# ESP32-C6 register map
Vendor: ESPRESSIF SYSTEMS (SHANGHAI) CO., LTD.; Series: ESP32 C-Series; File version: 5
CPU: RV32IMAC r0p0, little endian, no MPU, no FPU, 4 interrupt priority bits
Address unit: 32 bits
Registers are 32-bit, read-write, reset 0x0 unless marked. A register's access mark holds for its fields unless they carry their own. Offsets are from the block's base; [hi:lo] are bit positions; {n}, {i} and the like mark numbered series.

## DS — Digital Signature
Base 0x6008C000
{0x0+i} Y_MEM[{i}] (i=0..511) 8-bit access not given — memory that stores Y
{0x200+i} M_MEM[{i}] (i=0..511) 8-bit access not given — memory that stores M
{0x400+i} RB_MEM[{i}] (i=0..511) 8-bit access not given — memory that stores Rb
{0x600+i} BOX_MEM[{i}] (i=0..47) 8-bit access not given — memory that stores BOX
{0x630+i} IV_MEM[{i}] (i=0..15) 8-bit access not given — memory that stores IV
{0x800+i} X_MEM[{i}] (i=0..511) 8-bit access not given — memory that stores X
{0xA00+i} Z_MEM[{i}] (i=0..511) 8-bit access not given — memory that stores Z
0xE00 SET_START wo — DS start control register
  [0] SET_START — set this bit to start DS operation.
0xE04 SET_CONTINUE wo — DS continue control register
  [0] SET_CONTINUE — set this bit to continue DS operation.
0xE08 SET_FINISH wo — DS finish control register
  [0] SET_FINISH — Set this bit to finish DS process.
0xE0C QUERY_BUSY ro — DS query busy register
  [0] QUERY_BUSY — digital signature state. 1'b0: idle, 1'b1: busy
0xE10 QUERY_KEY_WRONG ro — DS query key-wrong counter register
  [3:0] QUERY_KEY_WRONG — digital signature key wrong counter
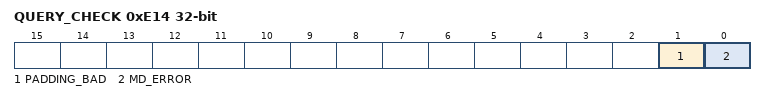
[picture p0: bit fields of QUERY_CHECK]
0xE14 QUERY_CHECK ro — DS query check result register
  [1] PADDING_BAD — padding checkout result. 1'b0: a good padding, 1'b1: a bad padding
  [0] MD_ERROR — MD checkout result. 1'b0: MD check pass, 1'b1: MD check fail
0xE20 DATE reset 0x20200618 — DS version control register
  [29:0] DATE — ds version information

## ECC — ECC (ECC Hardware Accelerator)
Base 0x6008B000
0x0C MULT_INT_RAW ro — ECC interrupt raw register, valid in level.
  [0] CALC_DONE_INT_RAW — The raw interrupt status bit for the ecc_calc_done_int interrupt
0x10 MULT_INT_ST ro — ECC interrupt status register.
  [0] CALC_DONE_INT_ST — The masked interrupt status bit for the ecc_calc_done_int interrupt
0x14 MULT_INT_ENA — ECC interrupt enable register.
  [0] CALC_DONE_INT_ENA — The interrupt enable bit for the ecc_calc_done_int interrupt
0x18 MULT_INT_CLR wo — ECC interrupt clear register.
  [0] CALC_DONE_INT_CLR — Set this bit to clear the ecc_calc_done_int interrupt
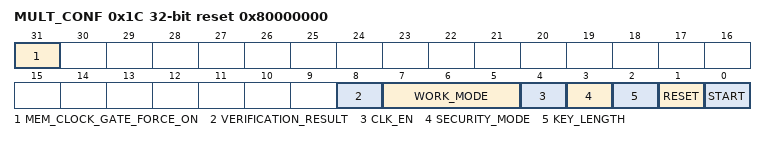
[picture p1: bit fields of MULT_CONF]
0x1C MULT_CONF access per field reset 0x80000000 — ECC configure register
  [31] MEM_CLOCK_GATE_FORCE_ON rw — ECC memory clock gate force on register
  [8] VERIFICATION_RESULT ro — The verification result bit of ECC Accelerator, only valid when calculation is done.
  [7:5] WORK_MODE rw — The work mode bits of ECC Accelerator. 0: Point Mult Mode. 1: Division mode. 2: Point verification mode. 3: Point Verif+mult mode. 4: Jacobian Point Mult Mode. 5: Reserved. 6: Jacobian Point Verification Mode. 7: Point Verif + Jacobian Mult Mode.
  [4] CLK_EN rw — Write 1 to force on register clock gate.
  [3] SECURITY_MODE rw — Reserved
  [2] KEY_LENGTH rw — The key length mode bit of ECC Accelerator. 0: P-192. 1: P-256.
  [1] RESET wo — Write 1 to reset ECC Accelerator.
  [0] START rw — Write 1 to start caculation of ECC Accelerator. This bit will be self-cleared after the caculatrion is done.
0xFC MULT_DATE reset 0x2201240 — Version control register
  [27:0] DATE — ECC mult version control register
{0x100+i} K_MEM[{i}] (i=0..31) 8-bit access not given — The memory that stores k.
{0x120+i} PX_MEM[{i}] (i=0..31) 8-bit access not given — The memory that stores Px.
{0x140+i} PY_MEM[{i}] (i=0..31) 8-bit access not given — The memory that stores Py.

## GPIO_SD — Sigma-Delta Modulation
Base 0x60004F00
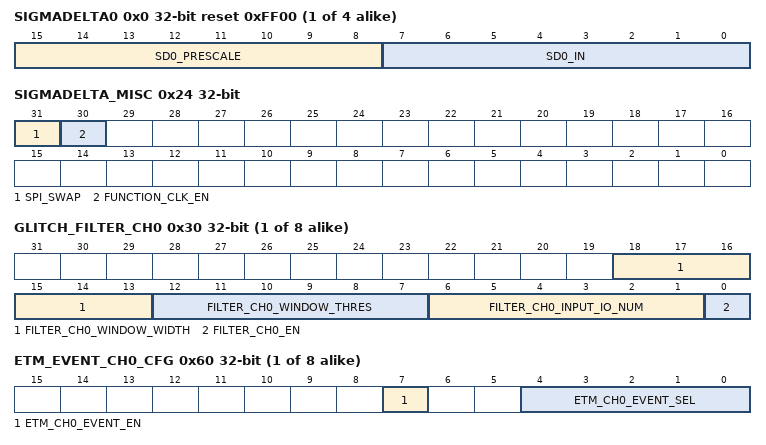
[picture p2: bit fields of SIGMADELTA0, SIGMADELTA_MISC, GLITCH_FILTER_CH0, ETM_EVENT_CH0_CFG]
{0x0+4i} SIGMADELTA{i} (i=0..3) reset 0xFF00 — Duty Cycle Configure Register of SDM{i}
  [15:8] SD0_PRESCALE — This field is used to set a divider value to divide APB clock.
  [7:0] SD0_IN — This field is used to configure the duty cycle of sigma delta modulation output.
0x20 CLOCK_GATE — Clock Gating Configure Register
  [0] CLK_EN — Clock enable bit of configuration registers for sigma delta modulation.
0x24 SIGMADELTA_MISC — MISC Register
  [31] SPI_SWAP — Reserved.
  [30] FUNCTION_CLK_EN — Clock enable bit of sigma delta modulation.
{0x30+4i} GLITCH_FILTER_CH{i} (i=0..7) — Glitch Filter Configure Register of Channel{i}
  [18:13] FILTER_CH0_WINDOW_WIDTH — Glitch Filter window width.
  [12:7] FILTER_CH0_WINDOW_THRES — Glitch Filter window threshold.
  [6:1] FILTER_CH0_INPUT_IO_NUM — Glitch Filter input io number.
  [0] FILTER_CH0_EN — Glitch Filter channel enable bit.
{0x60+4i} ETM_EVENT_CH{i}_CFG (i=0..7) — Etm Config register of Channel{i}
  [7] ETM_CH0_EVENT_EN — Etm event send enable bit.
  [4:0] ETM_CH0_EVENT_SEL — Etm event channel select gpio.
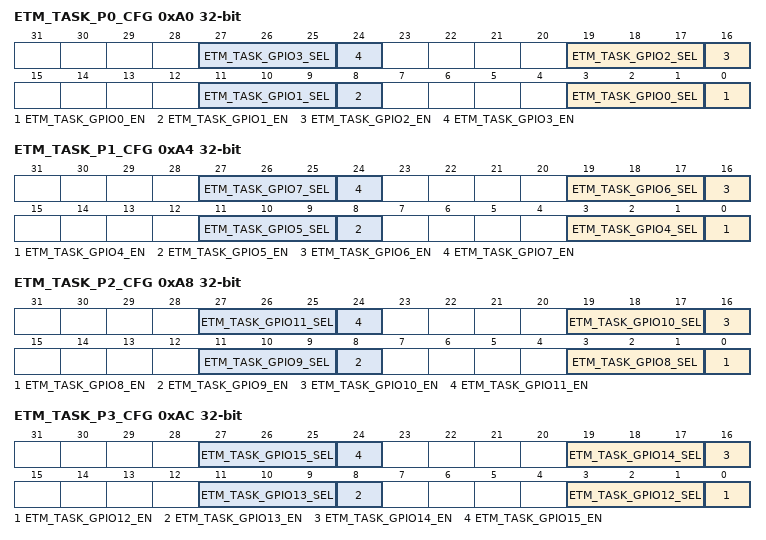
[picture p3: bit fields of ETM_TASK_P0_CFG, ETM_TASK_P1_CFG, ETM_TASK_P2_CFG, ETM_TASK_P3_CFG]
0xA0 ETM_TASK_P0_CFG — Etm Configure Register to decide which GPIO been chosen
  [8n+3:8n+1] ETM_TASK_GPIO{n}_SEL (n=0..3) — GPIO choose a etm task channel.
  [8n] ETM_TASK_GPIO{n}_EN (n=0..3) — Enable bit of GPIO response etm task.
0xA4 ETM_TASK_P1_CFG — Etm Configure Register to decide which GPIO been chosen
  [8n-29:8n-31] ETM_TASK_GPIO{n}_SEL (n=4..7) — GPIO choose a etm task channel.
  [8n-32] ETM_TASK_GPIO{n}_EN (n=4..7) — Enable bit of GPIO response etm task.
0xA8 ETM_TASK_P2_CFG — Etm Configure Register to decide which GPIO been chosen
  [8n-61:8n-63] ETM_TASK_GPIO{n}_SEL (n=8..11) — GPIO choose a etm task channel.
  [8n-64] ETM_TASK_GPIO{n}_EN (n=8..11) — Enable bit of GPIO response etm task.
0xAC ETM_TASK_P3_CFG — Etm Configure Register to decide which GPIO been chosen
  [8n-93:8n-95] ETM_TASK_GPIO{n}_SEL (n=12..15) — GPIO choose a etm task channel.
  [8n-96] ETM_TASK_GPIO{n}_EN (n=12..15) — Enable bit of GPIO response etm task.
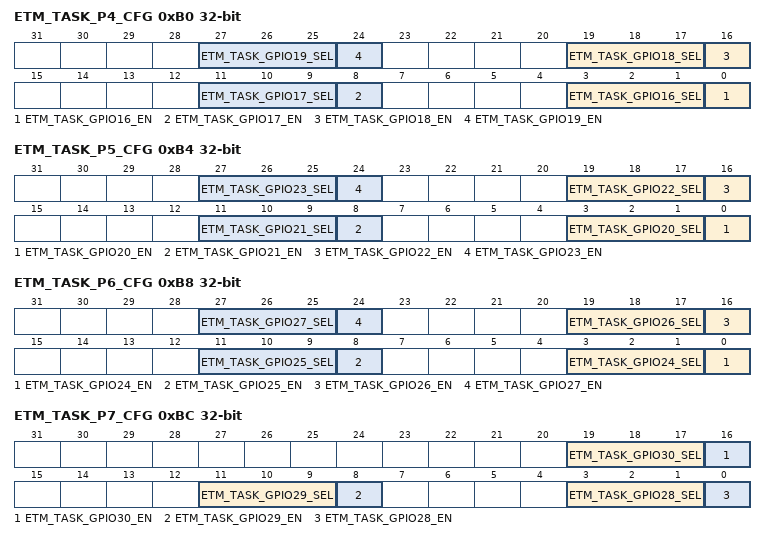
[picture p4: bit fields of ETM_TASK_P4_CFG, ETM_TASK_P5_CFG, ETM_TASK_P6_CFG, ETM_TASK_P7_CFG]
0xB0 ETM_TASK_P4_CFG — Etm Configure Register to decide which GPIO been chosen
  [8n-125:8n-127] ETM_TASK_GPIO{n}_SEL (n=16..19) — GPIO choose a etm task channel.
  [8n-128] ETM_TASK_GPIO{n}_EN (n=16..19) — Enable bit of GPIO response etm task.
0xB4 ETM_TASK_P5_CFG — Etm Configure Register to decide which GPIO been chosen
  [8n-157:8n-159] ETM_TASK_GPIO{n}_SEL (n=20..23) — GPIO choose a etm task channel.
  [8n-160] ETM_TASK_GPIO{n}_EN (n=20..23) — Enable bit of GPIO response etm task.
0xB8 ETM_TASK_P6_CFG — Etm Configure Register to decide which GPIO been chosen
  [8n-189:8n-191] ETM_TASK_GPIO{n}_SEL (n=24..27) — GPIO choose a etm task channel.
  [8n-192] ETM_TASK_GPIO{n}_EN (n=24..27) — Enable bit of GPIO response etm task.
0xBC ETM_TASK_P7_CFG — Etm Configure Register to decide which GPIO been chosen
  [19:17] ETM_TASK_GPIO30_SEL — GPIO choose a etm task channel.
  [16] ETM_TASK_GPIO30_EN — Enable bit of GPIO response etm task.
  [11:9] ETM_TASK_GPIO29_SEL — GPIO choose a etm task channel.
  [8] ETM_TASK_GPIO29_EN — Enable bit of GPIO response etm task.
  [3:1] ETM_TASK_GPIO28_SEL — GPIO choose a etm task channel.
  [0] ETM_TASK_GPIO28_EN — Enable bit of GPIO response etm task.
0xFC VERSION reset 0x2203050 — Version Control Register
  [27:0] GPIO_SD_DATE — Version control register.

## Notices in the file
Copyright 2023 Espressif Systems (Shanghai) PTE LTD
Licensed under the Apache License, Version 2.0 (the "License");
you may not use this file except in compliance with the License.
You may obtain a copy of the License at
http://www.apache.org/licenses/LICENSE-2.0
Unless required by applicable law or agreed to in writing, software
distributed under the License is distributed on an "AS IS" BASIS,
WITHOUT WARRANTIES OR CONDITIONS OF ANY KIND, either express or implied.
See the License for the specific language governing permissions and
limitations under the License.
